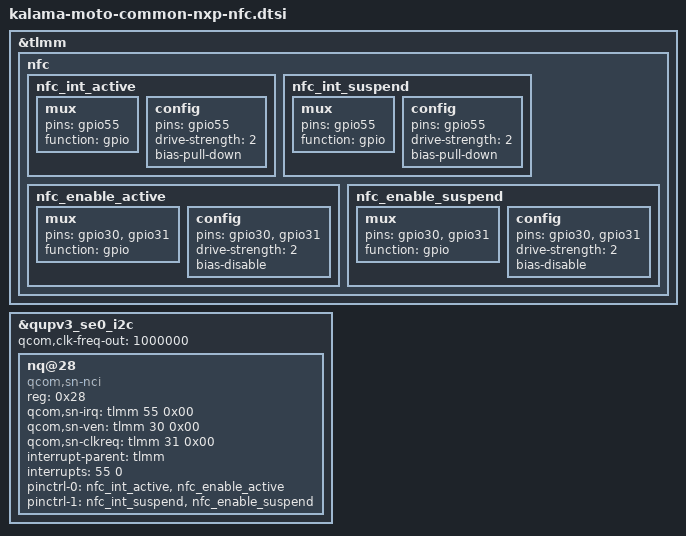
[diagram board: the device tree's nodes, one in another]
/* Copyright (c) 2021, The Linux Foundation. All rights reserved.
 *
 * This program is free software; you can redistribute it and/or modify
 * it under the terms of the GNU General Public License version 2 and
 * only version 2 as published by the Free Software Foundation.
 *
 * This program is distributed in the hope that it will be useful,
 * but WITHOUT ANY WARRANTY; without even the implied warranty of
 * MERCHANTABILITY or FITNESS FOR A PARTICULAR PURPOSE.  See the
 * GNU General Public License for more details.
 */

/* This file is used for 8550 device which use nxp nfc chipst */

&tlmm {
       nfc {
                nfc_int_active: nfc_int_active {
                        /* active state */
                        mux {
                                /* NFC Read Interrupt */
                                pins = "gpio55";
                                function = "gpio";
                        };

                        config {
                                pins = "gpio55";
                                drive-strength = <2>; /* 2 MA */
                                bias-pull-down;
                        };
                };

                nfc_int_suspend: nfc_int_suspend {
                        /* sleep state */
                        mux {
                                /* NFC Read Interrupt */
                                pins = "gpio55";
                                function = "gpio";
                        };

                        config {
                                pins = "gpio55";
                                drive-strength = <2>; /* 2 MA */
                                bias-pull-down;
                        };
                };

                nfc_enable_active: nfc_enable_active {
                        mux {
                                /* Enable, Firmware and Clock request gpios */
                                pins = "gpio30", "gpio31";
                                function = "gpio";
                        };

                        config {
                                pins = "gpio30", "gpio31";
                                drive-strength = <2>; /* 2 MA */
                                bias-disable;
                        };
                };

                nfc_enable_suspend: nfc_enable_suspend {
                        mux {
                                pins = "gpio30", "gpio31";
                                function = "gpio";
                        };

                        config {
                                pins = "gpio30", "gpio31";
                                drive-strength = <2>; /* 2 MA */
                                bias-disable;
                        };
                };
        };
};


&qupv3_se0_i2c {
        status = "ok";
        qcom,clk-freq-out = <1000000>;
        #address-cells = <1>;
        #size-cells = <0>;
        nq@28 {
                compatible = "qcom,sn-nci";
                reg = <0x28>;
                qcom,sn-irq = <&tlmm 55 0x00>;
                qcom,sn-ven = <&tlmm 30 0x00>;
                qcom,sn-clkreq = <&tlmm 31 0x00>;
                interrupt-parent = <&tlmm>;
                interrupts = <55 0>;
                interrupt-names = "nfc_irq";
                pinctrl-names = "nfc_active", "nfc_suspend";
                pinctrl-0 = <&nfc_int_active &nfc_enable_active>;
                pinctrl-1 = <&nfc_int_suspend &nfc_enable_suspend>;
        };
};
